# MKL28T7_CORE0 register map
Vendor: Freescale Semiconductor, Inc.; Series: Kinetis_L; File version: 1.6
CPU: CM0PLUS r0p0, little endian, no MPU, no FPU, VTOR, 2 interrupt priority bits
Registers are 32-bit, read-write, reset 0x0 unless marked. A register's access mark holds for its fields unless they carry their own. Offsets are from the block's base; [hi:lo] are bit positions; {n}, {i} and the like mark numbered series.

## SIM — System Integration Module
Base 0x40074000; register names take the prefix SIM_
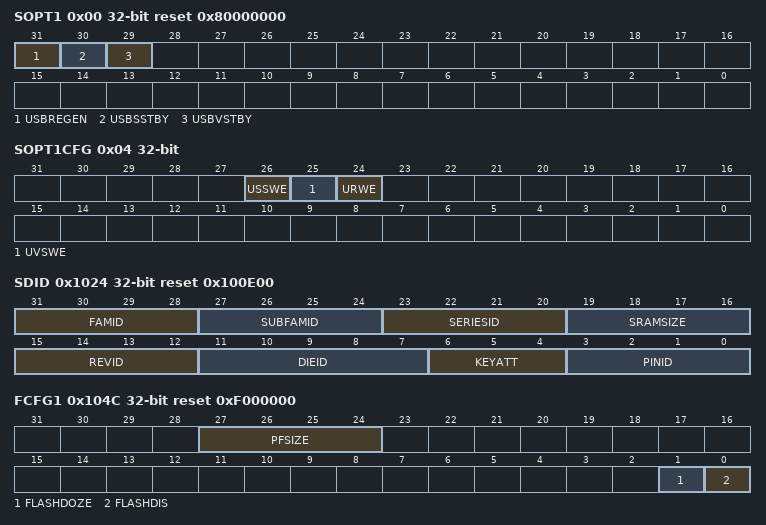
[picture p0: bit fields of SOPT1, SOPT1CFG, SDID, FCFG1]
0x00 SOPT1 reset 0x80000000 — System Options Register 1
  [31] USBREGEN — USB voltage regulator enable
    0=USB voltage regulator is disabled; 1=USB voltage regulator is enabled
  [30] USBSSTBY — USB voltage regulator in standby mode during Stop, VLPS, LLS and VLLS modes.
    0=USB voltage regulator not in standby during Stop, VLPS, LLS and VLLS modes; 1=USB voltage regulator in standby during Stop, VLPS, LLS and VLLS modes
  [29] USBVSTBY — USB voltage regulator in standby mode during VLPR and VLPW modes
    0=USB voltage regulator not in standby during VLPR and VLPW modes; 1=USB voltage regulator in standby during VLPR and VLPW modes
0x04 SOPT1CFG — SOPT1 Configuration Register
  [26] USSWE — USB voltage regulator stop standby write enable
    0=SOPT1 USBSSTB cannot be written; 1=SOPT1 USBSSTB can be written
  [25] UVSWE — USB voltage regulator VLP standby write enable
    0=SOPT1 USBVSTB cannot be written; 1=SOPT1 USBVSTB can be written
  [24] URWE — USB voltage regulator enable write enable
    0=SOPT1 USBREGEN cannot be written; 1=SOPT1 USBREGEN can be written
0x1024 SDID ro reset 0x100E00 — System Device Identification Register
  [31:28] FAMID — Kinetis family ID
    2=KL2x Family (USB)
  [27:24] SUBFAMID — Kinetis Sub-Family ID
    {v}=KLx{v} Subfamily (v=2..9)
  [23:20] SERIESID — Kinetis Series ID
    1=KL family
  [19:16] SRAMSIZE — System SRAM Size
    8=96 KB; 9=128 KB
  [15:12] REVID — Device Revision Number
  [11:7] DIEID — Device Die Number
  [6:4] KEYATT — Core configuration of the device.
    0=Cortex CM0+ Core; 1=Cortex CM0+ Core with additional Core (Core0 and Core1)
  [3:0] PINID — Pin count identification
    0=16-pin; 1=24-pin; 2=32-pin; 3=36-pin; 4=48-pin; 5=64-pin; 6=80-pin; 8=100-pin; 9=121-pin; 11=Custom pin-out(WLCSP)
0x104C FCFG1 reset 0xF000000 — Flash Configuration Register 1
  [27:24] PFSIZE ro — Program Flash Size
    5=64 KB of program flash memory, 2 KB protection region; 7=128 KB of program flash memory, 4 KB protection region; 9=256 KB of program flash memory, 8 KB protection region; 11=512 KB of program flash memory, 16 KB protection region
  [1] FLASHDOZE
    0=Flash remains enabled during Doze mode; 1=Flash is disabled for the duration of Doze mode
  [0] FLASHDIS — Flash Disable
    0=Flash is enabled; 1=Flash is disabled
0x1050 FCFG2 ro reset 0x7FA00000 — Flash Configuration Register 2
  [30:24] MAXADDR0 — Max Address lock
0x1058 UIDMH ro — Unique Identification Register Mid-High
  [15:0] UID — Unique Identification
0x105C UIDML ro — Unique Identification Register Mid Low
  [31:0] UID — Unique Identification
0x1060 UIDL ro — Unique Identification Register Low
  [31:0] UID — Unique Identification
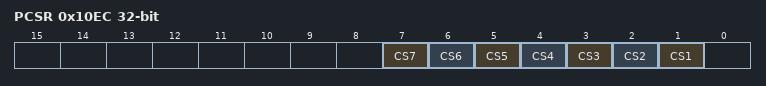
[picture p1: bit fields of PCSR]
0x10EC PCSR ro — Peripheral Clock Status Register
  [all] fields
    0=Clock not ready; 1=Clock ready
  [n] CS{n} (n=1..7) — Clock Source {n}

## TSTMR0 — Timestamp Timer
Base 0x400750F0; register names take the prefix TSTMR0_
0x00 L ro — Time Stamp Timer Register Low
  [31:0] VALUE — Time Stamp Timer Low
0x04 H ro — Time Stamp Timer Register High
  [23:0] VALUE — Time Stamp Timer High

## TSTMR1 — Timestamp Timer
Base 0x400F50F0; register names take the prefix TSTMR1_
Registers as TSTMR0.

## WDOG0 — Watchdog timer
Base 0x40076000; register names take the prefix WDOG0_
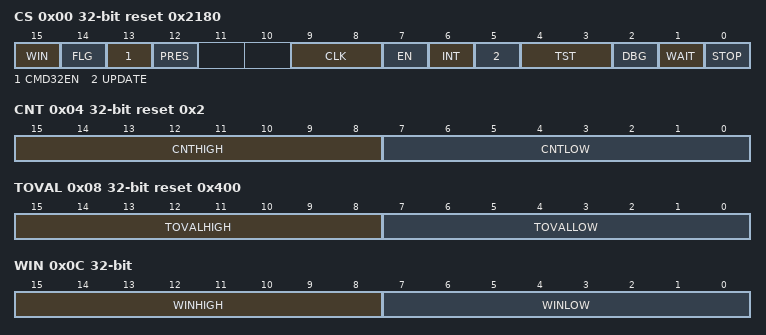
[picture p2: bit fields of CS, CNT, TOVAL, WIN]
0x00 CS reset 0x2180 — Watchdog Control and Status Register
  [15] WIN — Watchdog Window
    0=Window mode disabled; 1=Window mode enabled
  [14] FLG — Watchdog Interrupt Flag
    0=No interrupt occurred; 1=An interrupt occurred
  [13] CMD32EN — Enables or disables WDOG support for 32-bit (or 16-bit or 8-bit) refresh/unlock command write words
    0=Disables support for 32-bit (or 16-bit or 8-bit) refresh/unlock command write words; 1=Enables support for 32-bit (or 16-bit or 8-bit) refresh/unlock command write words
  [12] PRES — Watchdog Prescalar
    0=256 prescalar disabled; 1=256 prescalar enabled
  [9:8] CLK — Watchdog Clock
    0=Bus clock; 1=Internal low-power oscillator (LPOCLK); 2=8 MHz internal reference clock; 3=External clock source
  [7] EN — Watchdog Enable
    0=Watchdog disabled; 1=Watchdog enabled
  [6] INT — Watchdog Interrupt
    0=Watchdog interrupts are disabled. Watchdog resets are not delayed.; 1=Watchdog interrupts are enabled. Watchdog resets are delayed by 128 bus clocks from the interrupt vector fetch.
  [5] UPDATE — Allow updates
    0=Updates not allowed. After the initial configuration, the watchdog cannot be later modified without forcing a reset.; 1=Updates allowed. Software can modify the watchdog configuration registers within 128 bus clocks after performing the unlock write sequence.
  [4:3] TST — Watchdog Test
    0=Watchdog test mode disabled; 1=Watchdog user mode enabled. (Watchdog test mode disabled.) After testing the watchdog, software should use this setting to indicate that the watchdog is functioning normally in user mode.; 2=Watchdog test mode enabled, only the low byte is used. CNT[CNTLOW] is compared with TOVAL[TOVALLOW].; 3=Watchdog test mode enabled, only the high byte is used. CNT[CNTHIGH] is compared with TOVAL[TOVALHIGH].
  [2] DBG — Debug Enable
    0=Watchdog disabled in chip debug mode; 1=Watchdog enabled in chip debug mode
  [1] WAIT — Wait Enable
    0=Watchdog disabled in chip wait mode; 1=Watchdog enabled in chip wait mode
  [0] STOP — Stop Enable
    0=Watchdog disabled in chip stop mode; 1=Watchdog enabled in chip stop mode
0x04 CNT reset 0x2 — Watchdog Counter Register
  [15:8] CNTHIGH — High byte of the Watchdog Counter
  [7:0] CNTLOW — Low byte of the Watchdog Counter
0x08 TOVAL reset 0x400 — Watchdog Timeout Value Register
  [15:8] TOVALHIGH — High byte of the timeout value;
  [7:0] TOVALLOW — Low byte of the timeout value
0x0C WIN — Watchdog Window Register
  [15:8] WINHIGH — High byte of Watchdog Window
  [7:0] WINLOW — Low byte of Watchdog Window

## WDOG1 — Watchdog timer
Base 0x400F6000; register names take the prefix WDOG1_
Registers as WDOG0.
